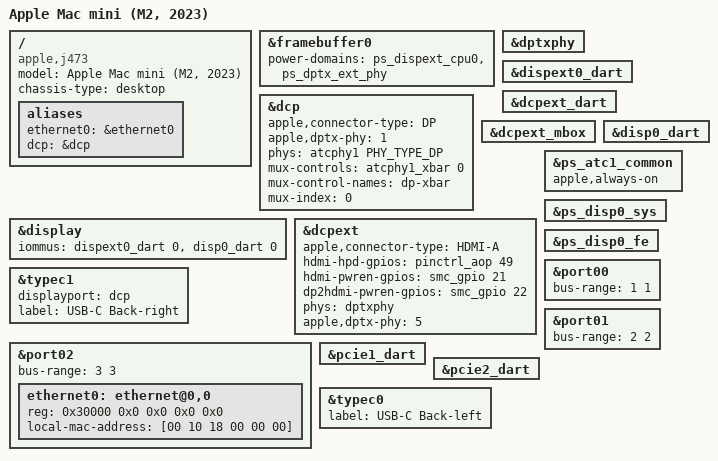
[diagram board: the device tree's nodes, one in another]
// SPDX-License-Identifier: GPL-2.0+ OR MIT
/*
 * Apple Mac mini (M2, 2023)
 *
 * target-type: J473
 *
 * Copyright The Asahi Linux Contributors
 */

/dts-v1/;

#define ENABLE_DCPEXT_TYPEC

#include "t8112.dtsi"
#include "t8112-jxxx.dtsi"

/ {
	compatible = "apple,j473", "apple,t8112", "apple,arm-platform";
	model = "Apple Mac mini (M2, 2023)";
	chassis-type = "desktop";

	aliases {
		ethernet0 = &ethernet0;
	};
};

 &framebuffer0 {
 	power-domains = <&ps_dispext_cpu0>, <&ps_dptx_ext_phy>;
 };

 &dptxphy {
 	status = "okay";
 };

 &dcp {
 	status = "disabled";
 };

 &display {
 	iommus = <&dispext0_dart 0>;
 };
 &dispext0_dart {
 	status = "okay";
 };
 &dcpext_dart {
 	status = "okay";
 };
 &dcpext_mbox {
 	status = "okay";
 };
 &dcpext {
 	status = "okay";
 	apple,connector-type = "HDMI-A";

 	/*  HDMI HPD gpio, used as interrupt*/
 	hdmi-hpd-gpios = <&pinctrl_aop 49 GPIO_ACTIVE_HIGH>;

 	hdmi-pwren-gpios = <&smc_gpio 21 GPIO_ACTIVE_HIGH>;
 	dp2hdmi-pwren-gpios = <&smc_gpio 22 GPIO_ACTIVE_HIGH>;

 	phys = <&dptxphy>;
 	phy-names = "dp-phy";
 	apple,dptx-phy = <5>;
 };

#ifdef ENABLE_DCPEXT_TYPEC
/ {
	aliases {
		dcp = &dcp;
	};
};

&display {
	/* dispext0_dart needs to be first for m1n1's */
	iommus = <&dispext0_dart 0>, <&disp0_dart 0>;
};

&disp0_dart {
	status = "okay";
};

&dcp {
	status = "okay";
	apple,connector-type = "DP";

	/* hacks */
	apple,dptx-phy = <1>;
	phys = <&atcphy1 PHY_TYPE_DP>;
	phy-names = "dp-phy";
	mux-controls = <&atcphy1_xbar 0>;
	mux-control-names = "dp-xbar";
	mux-index = <0>;
};

&dcpext {
	/delete-property/ mux-controls;
	/delete-property/ mux-control-names;
	/delete-property/ mux-index;
};

&typec1 {
	/* hacks */
	displayport = <&dcp>;
};

&ps_atc1_common {
	apple,always-on; /* Needs to stay on for DP-alt suspend/resume */
};
#endif

/*
 * Keep the power-domains used for the HDMI port on.
 */
&framebuffer0 {
	power-domains = <&ps_dispext_cpu0>, <&ps_dptx_ext_phy>;
};

/*
 * The M2 Mac mini uses dispext for the HDMI output so it's not necessary to
 * keep disp0 power-domains always-on.
 */
&ps_disp0_sys {
	/delete-property/ apple,always-on;
};

&ps_disp0_fe {
	/delete-property/ apple,always-on;
};

/*
 * Force the bus number assignments so that we can declare some of the
 * on-board devices and properties that are populated by the bootloader
 * (such as MAC addresses).
 */
&port00 {
	bus-range = <1 1>;
};

&port01 {
	bus-range = <2 2>;
	status = "okay";
};

&port02 {
	bus-range = <3 3>;
	status = "okay";
	ethernet0: ethernet@0,0 {
		reg = <0x30000 0x0 0x0 0x0 0x0>;
		/* To be filled by the loader */
		local-mac-address = [00 10 18 00 00 00];
	};
};

&pcie1_dart {
	status = "okay";
};

&pcie2_dart {
	status = "okay";
};

/*
 * Provide labels for the USB type C ports.
 */

&typec0 {
	label = "USB-C Back-left";
};

&typec1 {
	label = "USB-C Back-right";
};
